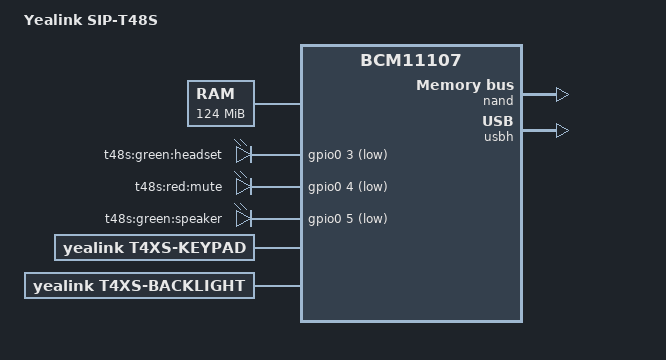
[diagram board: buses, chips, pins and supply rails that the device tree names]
// SPDX-License-Identifier: GPL-2.0
/*
 * Yealink SIP-T48S desk phone (hardware id 65).
 */
/dts-v1/;

#include "yealink-t4xs.dtsi"

/ {
	model = "Yealink SIP-T48S";
	compatible = "yealink,sip-t48s", "yealink,sip-t4xs", "brcm,bcm11188", "brcm,bcm11107";
	/* what the Holtek chip must answer; the kernel warns if it does not */
	yealink,hardware-id = <65>;

	/*
	 * 124 MB from 0x00400000 (the first 4 MB are not ours). The top 6 MB
	 * hold the frame buffers the boot loader set up; the LCD controller is
	 * scanning out of them when the kernel starts.
	 */
	memory@400000 {
		device_type = "memory";
		reg = <0x00400000 0x07c00000>;
	};

	/*
	 * The screen: the boot loader leaves the SoC's PL111 showing 800x480,
	 * 32 bits per pixel, from the first of the frame buffers below. We
	 * only draw into it.
	 */
	framebuffer {
		compatible = "simple-framebuffer";
		memory-region = <&fb_mem>;
		width = <800>;
		height = <480>;
		stride = <3200>;
		format = "x8r8g8b8";
	};

	/* the lamps inside three keys; the message lamp is on the Holtek chip */
	leds {
		compatible = "gpio-leds";

		led-headset {
			label = "t48s:green:headset";
			gpios = <&gpio0 3 GPIO_ACTIVE_LOW>;
			default-state = "off";
		};

		led-mute {
			label = "t48s:red:mute";
			gpios = <&gpio0 4 GPIO_ACTIVE_LOW>;
			default-state = "off";
		};

		led-speaker {
			label = "t48s:green:speaker";
			gpios = <&gpio0 5 GPIO_ACTIVE_LOW>;
			default-state = "off";
		};
	};

	/*
	 * The keys, as <Yealink's code for the matrix position (row * 8 +
	 * column + 1), Linux key code>. From Yealink's T48.qmap and pressed
	 * one by one (docs/keypad-touch-hw.md). The same table is built into
	 * drivers/t48s_keypad.c for a device tree without this node.
	 */
	keypad {
		compatible = "yealink,t4xs-keypad";
		yealink,keymap =
			<65 KEY_1>, <66 KEY_2>, <67 KEY_3>,
			<57 KEY_4>, <58 KEY_5>, <59 KEY_6>,
			<49 KEY_7>, <50 KEY_8>, <51 KEY_9>,
			<41 KEY_KPASTERISK>, <42 KEY_0>, <43 KEY_NUMERIC_POUND>,
			<68 KEY_UP>, <52 KEY_DOWN>, <61 KEY_LEFT>, <69 KEY_RIGHT>,
			<60 KEY_ENTER>,		/* OK */
			<53 KEY_BACKSPACE>,	/* X */
			<45 KEY_VOLUMEDOWN>, <44 KEY_VOLUMEUP>,
			<33 KEY_PROG1>,		/* Headset */
			<25 KEY_MUTE>,
			<34 KEY_MESSENGER>,	/* Message */
			<26 KEY_PAUSE>,		/* Hold */
			<35 KEY_AGAIN>,		/* Redial */
			<37 KEY_FORWARD>,	/* Transfer */
			<36 KEY_PROG2>;		/* Speakerphone */
	};

	/* the lamp behind the screen: enable on GPIO18, ten PWM steps (drivers/t48s_backlight.c) */
	backlight {
		compatible = "yealink,t4xs-backlight";
		yealink,enable-pin = <18>;
		yealink,pwm-fields = /bits/ 8 <27 24 21 18 15 12 9 6 3 0>;
	};

	reserved-memory {
		#address-cells = <1>;
		#size-cells = <1>;
		ranges;

		fb_mem: framebuffer@7a24000 {
			reg = <0x07a24000 0x005dc000>;
			no-map;
		};
	};
};

&nand {
	status = "okay";
};

/* the USB socket: only when U-Boot has started it (a start from a stick) */
&usbh {
	status = "okay";
};
